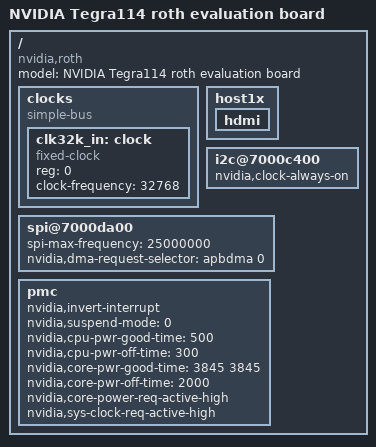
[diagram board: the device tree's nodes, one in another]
/*
 * arch/arm/boot/dts/tegra114-roth.dts
 *
 * Copyright (C) 2012-2014 NVIDIA Corporation. All rights reserved.
 *
 * This software is licensed under the terms of the GNU General Public
 * License version 2, as published by the Free Software Foundation, and
 * may be copied, distributed, and modified under those terms.
 *
 * This program is distributed in the hope that it will be useful,
 * but WITHOUT ANY WARRANTY; without even the implied warranty of
 * MERCHANTABILITY or FITNESS FOR A PARTICULAR PURPOSE.  See the
 * GNU General Public License for more details.
 *
 */

/dts-v1/;

/include/ "tegra114.dtsi"
#include <tegra114-platforms/tegra114-roth-gpio-default.dtsi>
#include <tegra114-platforms/tegra114-roth-pinmux.dtsi>

/ {
	model = "NVIDIA Tegra114 roth evaluation board";
	compatible = "nvidia,roth", "nvidia,tegra114";

	clocks {
		compatible = "simple-bus";
		#address-cells = <1>;
		#size-cells = <0>;

		clk32k_in: clock {
			compatible = "fixed-clock";
			reg=<0>;
			#clock-cells = <0>;
			clock-frequency = <32768>;
		};
	};

	host1x {
		hdmi {
			status = "okay";
		};
	};

	i2c@7000c400 {
		nvidia,clock-always-on;
	};

	spi@7000da00 {
		status = "okay";
		spi-max-frequency = <25000000>;
		nvidia,dma-request-selector = <&apbdma 0>;
	};

	pmc {
		status = "okay";
		nvidia,invert-interrupt;
		nvidia,suspend-mode = <0>;
		nvidia,cpu-pwr-good-time = <500>;
		nvidia,cpu-pwr-off-time = <300>;
		nvidia,core-pwr-good-time = <3845 3845>;
		nvidia,core-pwr-off-time = <2000>;
		nvidia,core-power-req-active-high;
		nvidia,sys-clock-req-active-high;
	};
};
